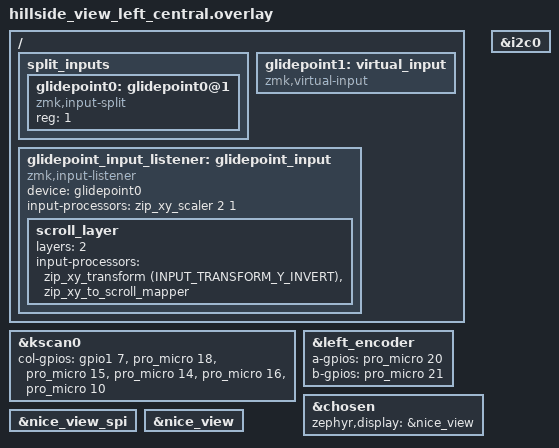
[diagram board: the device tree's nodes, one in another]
/*
 * Copyright (c) 2022 The ZMK Contributors
 *
 * SPDX-License-Identifier: MIT
 */

#include "hillside_view.dtsi"
#include <input/processors.dtsi>
#include <dt-bindings/zmk/input_transform.h>

&kscan0  {
    col-gpios
        = <&gpio1 7 GPIO_ACTIVE_HIGH>
        , <&pro_micro 18 GPIO_ACTIVE_HIGH>
        , <&pro_micro 15 GPIO_ACTIVE_HIGH>
        , <&pro_micro 14 GPIO_ACTIVE_HIGH>
        , <&pro_micro 16 GPIO_ACTIVE_HIGH>
        , <&pro_micro 10 GPIO_ACTIVE_HIGH>
        ;
};

&left_encoder {
    status = "okay";
    a-gpios = <&pro_micro 20 (GPIO_ACTIVE_HIGH | GPIO_PULL_UP)>;
    b-gpios = <&pro_micro 21 (GPIO_ACTIVE_HIGH | GPIO_PULL_UP)>;
};

&chosen {
    zephyr,display = &nice_view;
};

// nice view bus
&nice_view_spi {
    status = "okay";
};

&nice_view {
    status = "okay";
};

/* Left half as central - no dongle mode */

/* Delete the physical glidepoint0 from dtsi since left has no physical trackpad */
&i2c0 {
    /delete-node/ glidepoint@2a;
};

/ {
    /* Native ZMK split input support - receive right trackpad input from peripheral */
    split_inputs {
        #address-cells = <1>;
        #size-cells = <0>;

        /* Split device for right peripheral glidepoint (reg 1) - matches dongle pattern */
        glidepoint0: glidepoint0@1 {
            compatible = "zmk,input-split";
            reg = <1>;
        };
    };

    /* Virtual input device for keymap compatibility - matches dongle pattern */
    glidepoint1: virtual_input {
        compatible = "zmk,virtual-input";
    };

    /* Input listener for received pointer events from right trackpad - matches dongle pattern */
    glidepoint_input_listener: glidepoint_input {
        compatible = "zmk,input-listener";
        device = <&glidepoint0>;
        /* Default: 2x scaling for normal pointer movement */
        input-processors = <&zip_xy_scaler 2 1>;
        
        /* Layer-specific override: convert to scroll on SYM layer (layer 2) with inverted Y */
        scroll_layer {
            layers = <2>;
            input-processors = <&zip_xy_transform (INPUT_TRANSFORM_Y_INVERT)>, <&zip_xy_to_scroll_mapper>;
        };
    };
};
